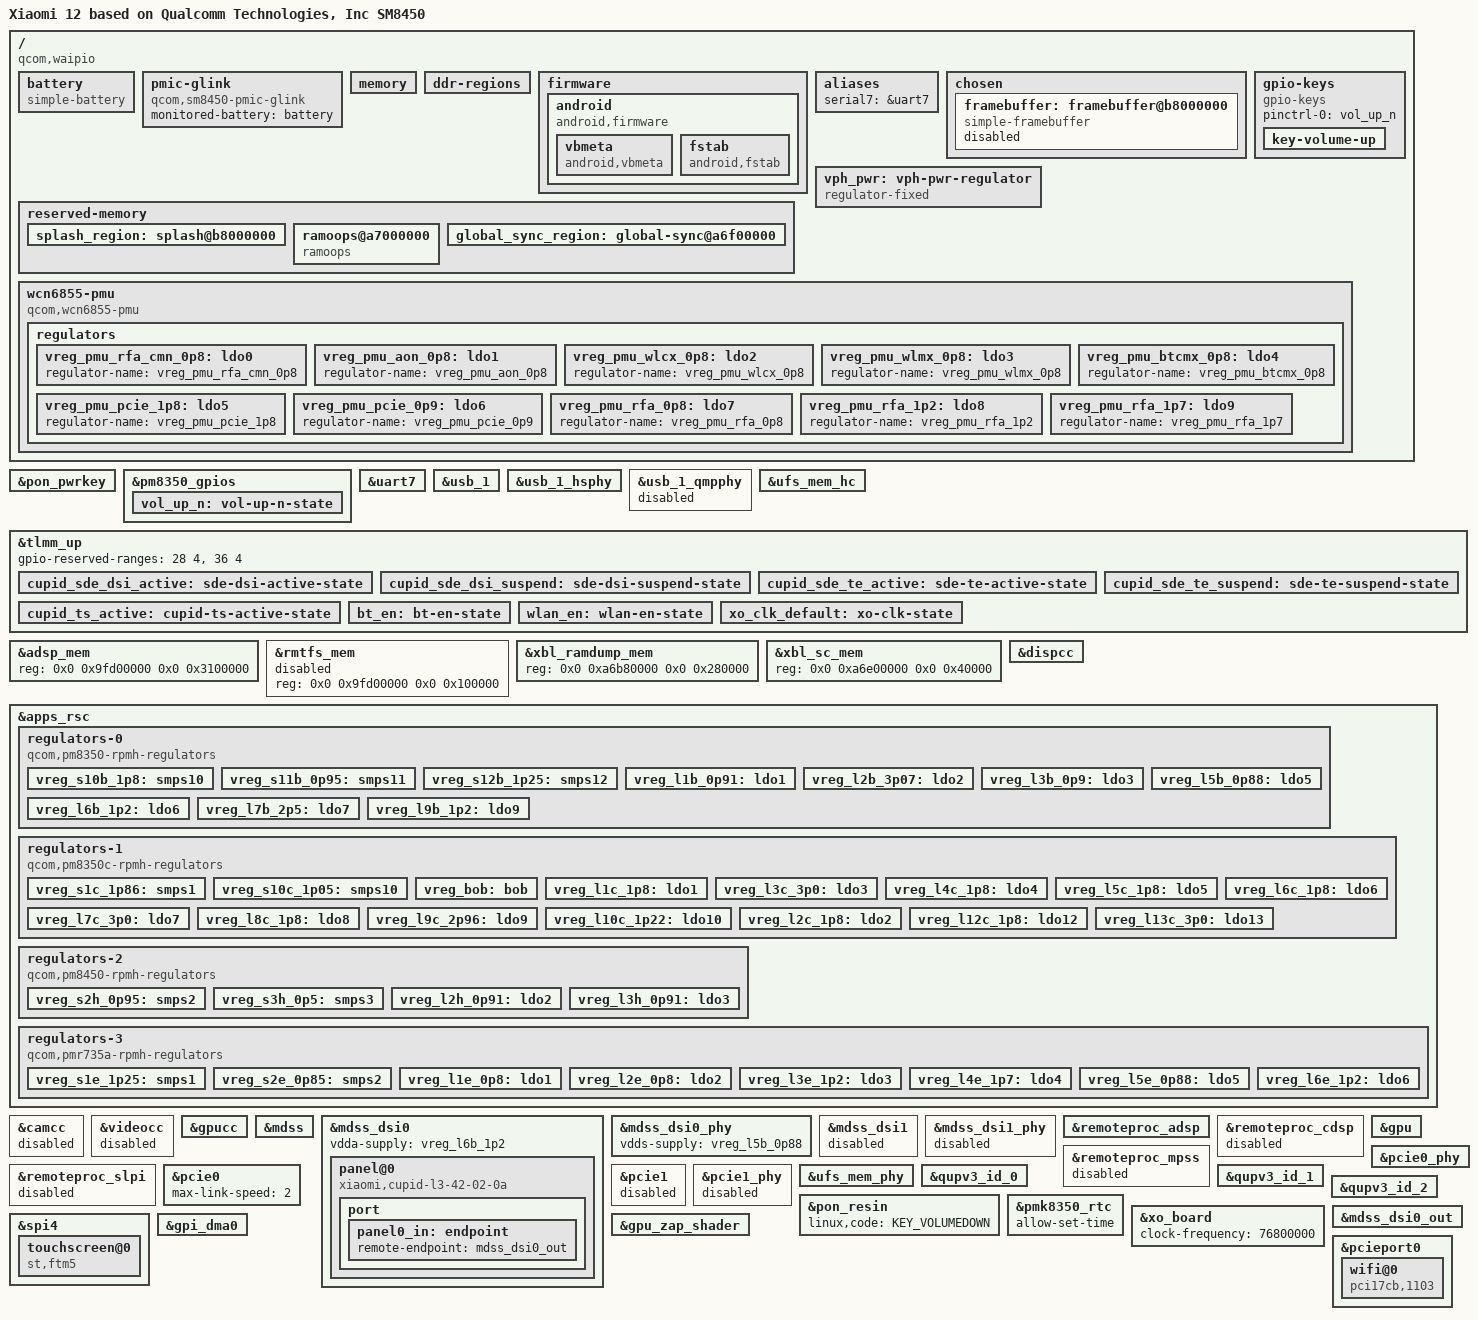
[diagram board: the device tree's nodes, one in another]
// SPDX-License-Identifier: GPL-2.0-only
/*
 * Board device tree for Xiaomi 12 (cupid) ??Qualcomm SM8450 (Snapdragon 8 Gen 1).
 *
 * All values from on-device forensics (2026-10-27):
 *   - runtime device tree (private/device-tree.tar, kernel 5.10.237 vendor build)
 *   - /proc/cmdline, fastboot getvar all, panel modes
 * Reference template: sm8475-xiaomi-marble.dts (same-generation Xiaomi port).
 *
 * Minimal boot set (android-mainline-port step 3): console, USB device mode,
 * UFS, keys, ramoops, borrowed firmware framebuffer. Peripherals (panel
 * native takeover, touch, audio, Wi-Fi) follow in later steps.
 */
/dts-v1/;

#include <dt-bindings/arm/qcom,ids.h>
#include <dt-bindings/gpio/gpio.h>
#include <dt-bindings/input/input.h>
#include <dt-bindings/pinctrl/qcom,pmic-gpio.h>
#include <dt-bindings/regulator/qcom,rpmh-regulator.h>

#include "sm8450.dtsi"
#include "pm8350.dtsi"
#include "pm8350b.dtsi"
#include "pm8350c.dtsi"
#include "pm8450.dtsi"
#include "pmk8350.dtsi"
#include "pmr735a.dtsi"
#include "sm8450-xiaomi-cupid-syms.dtsi"
#include "cupid-cpu-opps.dtsi"

/*
 * XBL allocates firmware carve-outs per device. The SoC dtsi placeholders
 * for adsp/xbl_ramdump/xbl_sc do not match this unit (forensics:
 * adsp@9fd00000, xbl_ramdump@a6b80000, xbl-sc@a6e00000) and are overridden
 * by label at the end of this file. mpss_mem@8bc00000 already matches.
 */

/ {
	model = "Xiaomi 12 based on Qualcomm Technologies, Inc SM8450";
	compatible = "qcom,waipio", "xiaomi,cupid", "qcom,sm8450";
	/*
	 * ABL picks the matching DTB out of the vendor_boot multi-DTB
	 * container by qcom,msm-id + qcom,board-id.
	 *
	 * SM8450 is Waipio: the stock container's waipio entry carries
	 * msm-id <0x1c9 0x10000>, board-id <0 0>. (Entry 0 of the same
	 * container is cape-v2 = SM8475, a different SoC ??do not copy it.)
	 * The values in the runtime /sys/firmware/fdt (<201 0 226 0>) are
	 * what the dtbo overlay wrote over the root afterwards.
	 */
	qcom,msm-id = <0x1c9 0x10000>;
	qcom,board-id = <0x0 0x0>;
	chassis-type = "handset";

	/*
	 * Battery/charger run in ADSP firmware (battmgr) over pmic_glink.
	 * 4500 mAh cell (spec); design voltage assumed ??verify on device.
	 */
	battery: battery {
		compatible = "simple-battery";
		charge-full-design-microamp-hours = <4500000>;
		voltage-min-design-microvolt = <3870000>;
	};

	pmic-glink {
		compatible = "qcom,sm8450-pmic-glink", "qcom,pmic-glink";
		#address-cells = <1>;
		#size-cells = <0>;
		monitored-battery = <&battery>;
	};

	/delete-node/ memory@a0000000;

	/*
	 * 12 GiB LPDDR5, six physical banks from the runtime DT + Android
	 * /proc/iomem System RAM. The stock base DTB leaves /memory empty for
	 * ABL to fill, but ABL does not fill OUR tree (it only patches the
	 * shape it shipped) ??leaving reg empty here means the kernel starts
	 * with zero memory and panics before it can print anything.
	 */
	memory {
		device_type = "memory";
		reg = <0x0 0x80000000 0x0 0x6a000000>,
		      <0x0 0xf4600000 0x0 0x0ba00000>,
		      <0x8 0x00000000 0x0 0x37500000>,
		      <0x8 0x37b00000 0x0 0x01e00000>,
		      <0x8 0x40000000 0x0 0xc0000000>,
		      <0x9 0x00000000 0x1 0x80000000>;
	};

	ddr-regions {
	};

	/* Stock base DTB carries these; keep the same shape for the ABL. */
	firmware {
		android {
			compatible = "android,firmware";

			vbmeta {
				compatible = "android,vbmeta";
				parts = "vbmeta,boot,init_boot,system,vendor,dtbo,recovery";
			};

			fstab {
				compatible = "android,fstab";
			};
		};
	};

	aliases {
		serial7 = &uart7;
	};

	chosen {
		/* reg 解析需要 cells；缺失时 framebuffer 的 reg 无法变成资源，
		 * simpledrm probe 以 -EINVAL 失败（2026-10-31 实测） */
		#address-cells = <2>;
		#size-cells = <2>;
		/*
		 * ABL reads /chosen/bootargs from the device tree (not just the
		 * boot.img header) and appends its own args. Keep it short ??the
		 * bootloader's buffer is ~512 bytes and silently truncates.
		 */
		bootargs = "cupid.fb=0xB8000000,1080,2400,1080,32 clk_ignore_unused pd_ignore_unused regulator_ignore_unused arm-smmu.disable_bypass=0 cpuidle.off=1 console=tty0 console=ttyMSM0,115200n8 quiet loglevel=3 oops=panic softlockup_panic=1 hung_task_panic=1 deferred_probe_timeout=15 panic=30 g_serial.enable=0 g_serial.use_acm=1 rdinit=/init";
		stdout-path = "serial7:115200n8";

		/*
		 * Borrowed firmware display (splash_region, forensics: 0xb8000000
		 * 43 MiB, 1080x2400). First-boot only; native takeover in step 4.
		 * Panel: qcom,mdss_dsi_l3_42_02_0a_dsc_cmd (SeeYA OLED).
		 */
		framebuffer: framebuffer@b8000000 {
			compatible = "simple-framebuffer";
			/* 7.2+ simpledrm 首选 memory-region（aperture 管理），reg 仅回退 */
			memory-region = <&splash_region>;
			reg = <0x0 0xb8000000 0x0 0x2b00000>;
			width = <1080>;
			height = <2400>;
			stride = <(1080 * 4)>;
			format = "a8r8g8b8";
			/* keep the display AXI clock alive ??without it writes to
			 * the borrowed framebuffer do not reach the panel */
			clocks = <&gcc GCC_DISP_HF_AXI_CLK>;
		};
	};

	reserved-memory {
		splash_region: splash@b8000000 {
			reg = <0x0 0xb8000000 0x0 0x2b00000>;
			no-map;
		};

		ramoops@a7000000 {
			compatible = "ramoops";
			reg = <0x0 0xa7000000 0x0 0x400000>;
			record-size = <0x100000>;
			pmsg-size = <0x100000>;
			console-size = <0x200000>;
		};

		global_sync_region: global-sync@a6f00000 {
			reg = <0x0 0xa6f00000 0x0 0x100000>;
			no-map;
		};

		/* TODO(step 6 remotes): slpi@88000000/cdsp@89900000 placeholders
		 * already match this unit; add adsp_heap/audio_cma/spss/spu/va_md/
		 * camera/video/cvp/demura when those subsystems are enabled. */
	};

	gpio-keys {
		compatible = "gpio-keys";
		pinctrl-0 = <&vol_up_n>;
		pinctrl-names = "default";

		key-volume-up {
			label = "Volume Up";
			linux,code = <KEY_VOLUMEUP>;
			/* forensics: pm8350@1 pinctrl key_vol_up; gpio6 per
			 * marble reference ??verify pins in key_vol_up_default */
			gpios = <&pm8350_gpios 6 GPIO_ACTIVE_LOW>;
			debounce-interval = <15>;
			wakeup-source;
		};
	};
};

&pon_pwrkey {
	status = "okay";
};

&pm8350_gpios {
	vol_up_n: vol-up-n-state {
		pins = "gpio6";
		function = PMIC_GPIO_FUNC_NORMAL;
		power-source = <1>;
		bias-pull-up;
		input-enable;
	};
};

&uart7 {
	status = "okay";
};

&usb_1 {
	status = "okay";
	/* netboot phase: device mode for USB NCM debug link.
	 * sm8450.dtsi merges the dwc3 core into usb_1 itself. */
	dr_mode = "peripheral";
};

/* Both PHYs are disabled in sm8450.dtsi ??without them the dwc3
 * controller defers forever and no UDC appears for the gadget. */
&usb_1_hsphy {
	status = "okay";
};

&usb_1_qmpphy {
	status = "okay";
};

&ufs_mem_hc {
	status = "okay";
};

/*
 * GPIO 28-31 / 36-39 belong to TrustZone (stock waipio DTB:
 * qcom,gpios-reserved = <0x1c 0x1d 0x1e 0x1f 0x24 0x25 0x26 0x27>).
 * Without gpio-reserved-ranges the pinctrl driver touches their
 * registers during probe -> XPU violation -> SoC hang + watchdog reset
 * (same failure mode as Xiaomi 13/fuxi, see fuxi-linux notes).
 */
&tlmm_up {
	gpio-reserved-ranges = <28 4>, <36 4>;
};

/* XBL firmware carve-outs, on-device values (forensics) */
&adsp_mem {
	reg = <0x0 0x9fd00000 0x0 0x3100000>;
};

&rmtfs_mem {
	/* No standalone rmtfs on this unit; the dtsi placeholder address
	 * (0x9fd00000) is the ADSP region here. Shrink inside the ADSP
	 * reservation ??harmless overlap, revisited when MSS is enabled. */
	reg = <0x0 0x9fd00000 0x0 0x100000>;
};

&xbl_ramdump_mem {
	reg = <0x0 0xa6b80000 0x0 0x280000>;
};

&xbl_sc_mem {
	reg = <0x0 0xa6e00000 0x0 0x40000>;
};


/*
 * CUPID_MINIMAL_DISABLE (fuxi-style minimal bring-up):
 * sm8450.dtsi leaves every clock controller enabled by default. On this
 * first-batch waipio unit several of them probe hardware regions that
 * hang the SoC (freeze seen at gcc GDSC init and clk driver probes).
 * Keep only gcc + rpmhcc; everything else with a driver in the config
 * gets disabled until its consumer is actually brought up.
 */
&dispcc { status = "disabled"; };

/* apps_rsc 的 power-domains = <&cluster_pd> 依赖 CPU PM domain provider
 * （cpuidle-psci-domain）。本机 PSCI 固件上 SET_SUSPEND_MODE 可能失败导致
 * 整个 provider 注册回滚 -> rpmh-rsc 永久 defer -> 整条 RPMH 链死锁。
 * 先把该属性去掉，让 rpmh-rsc 无 genpd 依赖地 probe（bring-up 期）。 */
&apps_rsc {
	/delete-property/ power-domains;
};
&camcc  { status = "disabled"; };
&videocc { status = "disabled"; };
&gpucc  { status = "disabled"; };

/* display pipe stays dark until the panel driver lands (step 4) */
&mdss { status = "disabled"; };
&mdss_dsi0 { status = "disabled"; };
&mdss_dsi0_phy { status = "disabled"; };
&mdss_dsi1 { status = "disabled"; };
&mdss_dsi1_phy { status = "disabled"; };

/* remotes need firmware we do not ship yet */
&remoteproc_adsp { status = "disabled"; };
&remoteproc_cdsp { status = "disabled"; };
&remoteproc_mpss { status = "disabled"; };
&remoteproc_slpi { status = "disabled"; };

/* GPU not in minimal config */
&gpu { status = "disabled"; };

/* PCIe/WiFi for a later step */
&pcie0 { status = "disabled"; };
&pcie0_phy { status = "disabled"; };
&pcie1 { status = "disabled"; };
&pcie1_phy { status = "disabled"; };

/* ===== FUXI_ALIGNMENT_BLOCK =====
 * Regulators + UFS/USB wiring copied from the E-011 graft (originally from
 * sm8450-qrd.dts). It made ABL reject the image when the DTB was shipped in
 * the boot image, but with CUPID_FORCE_BUILTIN_DTB ABL never sees our tree,
 * so the graft is safe now. fuxi proves the same structure boots on Xiaomi
 * hardware of the adjacent generation.
 */
/* ===== regulators: copied from sm8450-qrd.dts (same SoC + same PMIC set) ===== */
/ {
	vph_pwr: vph-pwr-regulator {
		compatible = "regulator-fixed";
		regulator-name = "vph_pwr";
		regulator-min-microvolt = <3700000>;
		regulator-max-microvolt = <3700000>;

		regulator-always-on;
		regulator-boot-on;
	};

};

&apps_rsc {
	regulators-0 {
		compatible = "qcom,pm8350-rpmh-regulators";
		qcom,pmic-id = "b";

		vdd-s1-supply = <&vph_pwr>;
		vdd-s2-supply = <&vph_pwr>;
		vdd-s3-supply = <&vph_pwr>;
		vdd-s4-supply = <&vph_pwr>;
		vdd-s5-supply = <&vph_pwr>;
		vdd-s6-supply = <&vph_pwr>;
		vdd-s7-supply = <&vph_pwr>;
		vdd-s8-supply = <&vph_pwr>;
		vdd-s9-supply = <&vph_pwr>;
		vdd-s10-supply = <&vph_pwr>;
		vdd-s11-supply = <&vph_pwr>;
		vdd-s12-supply = <&vph_pwr>;

		vdd-l1-l4-supply = <&vreg_s11b_0p95>;
		vdd-l2-l7-supply = <&vreg_bob>;
		vdd-l3-l5-supply = <&vreg_bob>;
		vdd-l6-l9-l10-supply = <&vreg_s12b_1p25>;
		vdd-l8-supply = <&vreg_s2h_0p95>;

		vreg_s10b_1p8: smps10 {
			regulator-name = "vreg_s10b_1p8";
			regulator-min-microvolt = <1800000>;
			regulator-max-microvolt = <1800000>;
		};

		vreg_s11b_0p95: smps11 {
			regulator-name = "vreg_s11b_0p95";
			regulator-min-microvolt = <848000>;
			regulator-max-microvolt = <1104000>;
		};

		vreg_s12b_1p25: smps12 {
			regulator-name = "vreg_s12b_1p25";
			regulator-min-microvolt = <1224000>;
			regulator-max-microvolt = <1400000>;
		};

		vreg_l1b_0p91: ldo1 {
			regulator-name = "vreg_l1b_0p91";
			regulator-min-microvolt = <912000>;
			regulator-max-microvolt = <920000>;
			regulator-initial-mode = <RPMH_REGULATOR_MODE_HPM>;
		};

		vreg_l2b_3p07: ldo2 {
			regulator-name = "vreg_l2b_3p07";
			regulator-min-microvolt = <3072000>;
			regulator-max-microvolt = <3072000>;
			regulator-initial-mode = <RPMH_REGULATOR_MODE_HPM>;
		};

		vreg_l3b_0p9: ldo3 {
			regulator-name = "vreg_l3b_0p9";
			regulator-min-microvolt = <904000>;
			regulator-max-microvolt = <904000>;
			regulator-initial-mode = <RPMH_REGULATOR_MODE_HPM>;
		};

		vreg_l5b_0p88: ldo5 {
			regulator-name = "vreg_l5b_0p88";
			regulator-min-microvolt = <880000>;
			regulator-max-microvolt = <888000>;
			regulator-initial-mode = <RPMH_REGULATOR_MODE_HPM>;
		};

		vreg_l6b_1p2: ldo6 {
			regulator-name = "vreg_l6b_1p2";
			regulator-min-microvolt = <1200000>;
			regulator-max-microvolt = <1200000>;
			regulator-initial-mode = <RPMH_REGULATOR_MODE_HPM>;
		};

		vreg_l7b_2p5: ldo7 {
			regulator-name = "vreg_l7b_2p5";
			regulator-min-microvolt = <2504000>;
			regulator-max-microvolt = <2504000>;
			regulator-initial-mode = <RPMH_REGULATOR_MODE_HPM>;
		};

		vreg_l9b_1p2: ldo9 {
			regulator-name = "vreg_l9b_1p2";
			regulator-min-microvolt = <1200000>;
			regulator-max-microvolt = <1200000>;
			regulator-initial-mode = <RPMH_REGULATOR_MODE_HPM>;
		};
	};

	regulators-1 {
		compatible = "qcom,pm8350c-rpmh-regulators";
		qcom,pmic-id = "c";

		vdd-s1-supply = <&vph_pwr>;
		vdd-s2-supply = <&vph_pwr>;
		vdd-s3-supply = <&vph_pwr>;
		vdd-s4-supply = <&vph_pwr>;
		vdd-s5-supply = <&vph_pwr>;
		vdd-s6-supply = <&vph_pwr>;
		vdd-s7-supply = <&vph_pwr>;
		vdd-s8-supply = <&vph_pwr>;
		vdd-s9-supply = <&vph_pwr>;
		vdd-s10-supply = <&vph_pwr>;

		vdd-l1-l12-supply = <&vreg_bob>;
		vdd-l2-l8-supply = <&vreg_bob>;
		vdd-l3-l4-l5-l7-l13-supply = <&vreg_bob>;
		vdd-l6-l9-l11-supply = <&vreg_bob>;

		vdd-bob-supply = <&vph_pwr>;

		vreg_s1c_1p86: smps1 {
			regulator-name = "vreg_s1c_1p86";
			regulator-min-microvolt = <1800000>;
			regulator-max-microvolt = <2024000>;
		};

		vreg_s10c_1p05: smps10 {
			regulator-name = "vreg_s10c_1p05";
			regulator-min-microvolt = <1000000>;
			regulator-max-microvolt = <1100000>;
		};

		vreg_bob: bob {
			regulator-name = "vreg_bob";
			regulator-min-microvolt = <3008000>;
			regulator-max-microvolt = <3960000>;
			regulator-initial-mode = <RPMH_REGULATOR_MODE_AUTO>;
		};

		vreg_l1c_1p8: ldo1 {
			regulator-name = "vreg_l1c_1p8";
			regulator-min-microvolt = <1800000>;
			regulator-max-microvolt = <1800000>;
			regulator-initial-mode = <RPMH_REGULATOR_MODE_HPM>;
		};

		vreg_l3c_3p0: ldo3 {
			regulator-name = "vreg_l3c_3p0";
			regulator-min-microvolt = <3296000>;
			regulator-max-microvolt = <3304000>;
			regulator-initial-mode = <RPMH_REGULATOR_MODE_HPM>;
		};

		vreg_l4c_1p8: ldo4 {
			regulator-name = "vreg_l4c_1p8";
			regulator-min-microvolt = <1704000>;
			regulator-max-microvolt = <3000000>;
			regulator-initial-mode = <RPMH_REGULATOR_MODE_HPM>;
		};

		vreg_l5c_1p8: ldo5 {
			regulator-name = "vreg_l5c_1p8";
			regulator-min-microvolt = <1704000>;
			regulator-max-microvolt = <3000000>;
			regulator-initial-mode = <RPMH_REGULATOR_MODE_HPM>;
		};

		vreg_l6c_1p8: ldo6 {
			regulator-name = "vreg_l6c_1p8";
			regulator-min-microvolt = <1800000>;
			regulator-max-microvolt = <3008000>;
			regulator-initial-mode = <RPMH_REGULATOR_MODE_HPM>;
		};

		vreg_l7c_3p0: ldo7 {
			regulator-name = "vreg_l7c_3p0";
			regulator-min-microvolt = <3008000>;
			regulator-max-microvolt = <3008000>;
			regulator-initial-mode = <RPMH_REGULATOR_MODE_HPM>;
		};

		vreg_l8c_1p8: ldo8 {
			regulator-name = "vreg_l8c_1p8";
			regulator-min-microvolt = <1800000>;
			regulator-max-microvolt = <1800000>;
			regulator-initial-mode = <RPMH_REGULATOR_MODE_HPM>;
		};

		vreg_l9c_2p96: ldo9 {
			regulator-name = "vreg_l9c_2p96";
			regulator-min-microvolt = <2960000>;
			regulator-max-microvolt = <3008000>;
			regulator-initial-mode = <RPMH_REGULATOR_MODE_HPM>;
		};

		vreg_l10c_1p22: ldo10 {
			regulator-name = "vreg_l10c_1p22";
			regulator-min-microvolt = <1200000>;
			regulator-max-microvolt = <1220000>;
			regulator-initial-mode = <RPMH_REGULATOR_MODE_HPM>;
		};

		vreg_l2c_1p8: ldo2 {
			regulator-name = "vreg_l2c_1p8";
			regulator-min-microvolt = <1800000>;
			regulator-max-microvolt = <1800000>;
			regulator-initial-mode = <RPMH_REGULATOR_MODE_HPM>;
		};

		vreg_l12c_1p8: ldo12 {
			regulator-name = "vreg_l12c_1p8";
			regulator-min-microvolt = <1800000>;
			regulator-max-microvolt = <1968000>;
			regulator-initial-mode = <RPMH_REGULATOR_MODE_HPM>;
		};

		vreg_l13c_3p0: ldo13 {
			regulator-name = "vreg_l13c_3p0";
			regulator-min-microvolt = <3000000>;
			regulator-max-microvolt = <3000000>;
			regulator-initial-mode = <RPMH_REGULATOR_MODE_HPM>;
		};
	};

	regulators-2 {
		compatible = "qcom,pm8450-rpmh-regulators";
		qcom,pmic-id = "h";

		vdd-s1-supply = <&vph_pwr>;
		vdd-s2-supply = <&vph_pwr>;
		vdd-s3-supply = <&vph_pwr>;
		vdd-s4-supply = <&vph_pwr>;
		vdd-s5-supply = <&vph_pwr>;
		vdd-s6-supply = <&vph_pwr>;

		vdd-l2-supply = <&vreg_bob>;
		vdd-l3-supply = <&vreg_bob>;
		vdd-l4-supply = <&vreg_bob>;

		vreg_s2h_0p95: smps2 {
			regulator-name = "vreg_s2h_0p95";
			regulator-min-microvolt = <848000>;
			regulator-max-microvolt = <1104000>;
		};

		vreg_s3h_0p5: smps3 {
			regulator-name = "vreg_s3h_0p5";
			regulator-min-microvolt = <500000>;
			regulator-max-microvolt = <500000>;
		};

		vreg_l2h_0p91: ldo2 {
			regulator-name = "vreg_l2h_0p91";
			regulator-min-microvolt = <880000>;
			regulator-max-microvolt = <912000>;
			regulator-initial-mode = <RPMH_REGULATOR_MODE_HPM>;
		};

		vreg_l3h_0p91: ldo3 {
			regulator-name = "vreg_l3h_0p91";
			regulator-min-microvolt = <912000>;
			regulator-max-microvolt = <912000>;
			regulator-initial-mode = <RPMH_REGULATOR_MODE_HPM>;
		};
	};

	regulators-3 {
		compatible = "qcom,pmr735a-rpmh-regulators";
		qcom,pmic-id = "e";

		vdd-s1-supply = <&vph_pwr>;
		vdd-s2-supply = <&vph_pwr>;
		vdd-s3-supply = <&vph_pwr>;

		vdd-l1-l2-supply = <&vreg_s2e_0p85>;
		vdd-l3-supply = <&vreg_s1e_1p25>;
		vdd-l4-supply = <&vreg_s1c_1p86>;
		vdd-l5-l6-supply = <&vreg_s1c_1p86>;
		vdd-l7-bob-supply = <&vreg_bob>;

		vreg_s1e_1p25: smps1 {
			regulator-name = "vreg_s1e_1p25";
			regulator-min-microvolt = <1200000>;
			regulator-max-microvolt = <1296000>;
		};

		vreg_s2e_0p85: smps2 {
			regulator-name = "vreg_s2e_0p85";
			regulator-min-microvolt = <500000>;
			regulator-max-microvolt = <1040000>;
		};

		vreg_l1e_0p8: ldo1 {
			regulator-name = "vreg_l1e_0p8";
			regulator-min-microvolt = <800000>;
			regulator-max-microvolt = <800000>;
		};

		vreg_l2e_0p8: ldo2 {
			regulator-name = "vreg_l2e_0p8";
			regulator-min-microvolt = <800000>;
			regulator-max-microvolt = <800000>;
		};

		vreg_l3e_1p2: ldo3 {
			regulator-name = "vreg_l3e_1p2";
			regulator-min-microvolt = <1200000>;
			regulator-max-microvolt = <1200000>;
		};

		vreg_l4e_1p7: ldo4 {
			regulator-name = "vreg_l4e_1p7";
			regulator-min-microvolt = <1776000>;
			regulator-max-microvolt = <1776000>;
		};

		vreg_l5e_0p88: ldo5 {
			regulator-name = "vreg_l5e_0p88";
			regulator-min-microvolt = <880000>;
			regulator-max-microvolt = <880000>;
		};

		vreg_l6e_1p2: ldo6 {
			regulator-name = "vreg_l6e_1p2";
			regulator-min-microvolt = <1200000>;
			regulator-max-microvolt = <1200000>;
		};
	};
};

/* ===== UFS / USB wiring (from sm8450-qrd.dts, verified against live DT) ===== */
&ufs_mem_hc {
	status = "okay";
	reset-gpios = <&tlmm_up 210 GPIO_ACTIVE_LOW>;
	vcc-supply = <&vreg_l7b_2p5>;
	vcc-max-microamp = <1100000>;
	vccq-supply = <&vreg_l9b_1p2>;
	vccq-max-microamp = <1200000>;
	vdd-hba-supply = <&vreg_l9b_1p2>;
};

&ufs_mem_phy {
	status = "okay";
	vdda-phy-supply = <&vreg_l5b_0p88>;
	vdda-pll-supply = <&vreg_l6b_1p2>;
};

&usb_1_hsphy {
	status = "okay";
	vdda-pll-supply = <&vreg_l5b_0p88>;
	vdda18-supply = <&vreg_l1c_1p8>;
	vdda33-supply = <&vreg_l2b_3p07>;
};

/* fuxi alignment: QUP wrappers + GPI DMA (skill pitfall L78-83: without
 * these, serial engines never register), xo_board freq, pon_resin key,
 * eUSB2 repeater supplies */
&qupv3_id_0 { status = "okay"; };
&qupv3_id_1 { status = "okay"; };
&qupv3_id_2 { status = "okay"; };

&pon_resin {
	linux,code = <KEY_VOLUMEDOWN>;
	status = "okay";
};

/* PMK8350 RTC: the only time source that survives a power cycle. */
&pmk8350_rtc {
	allow-set-time;
	status = "okay";
};

&xo_board {
	clock-frequency = <76800000>;
};

/* FUXI_USB_ALIGN: skill usb-and-storage.md L123 ? QMP USB3/DP PHY ??????
 * ???????????fuxi ?????? HS PHY?USB2 ????QMP ???
 * ? UTMI ? pipe ?????"??????"??? USB ??? */
&usb_1 {
	/delete-property/ usb-role-switch;
	phys = <&usb_1_hsphy>;
	phy-names = "usb2-phy";
	maximum-speed = "high-speed";
	qcom,select-utmi-as-pipe-clk;
	dr_mode = "peripheral";
	status = "okay";
};

&usb_1_qmpphy {
	status = "disabled";
};


/* ===== DISPLAY (v-disp variant): MSM/DPU + DSI0 + 5nm PHY + panel ===== */
&framebuffer {
	status = "disabled";
};

&dispcc {
	status = "okay";
};

&mdss {
	status = "okay";
};

&mdss_dsi0 {
	vdda-supply = <&vreg_l6b_1p2>;
	status = "okay";

	panel@0 {
		compatible = "xiaomi,cupid-l3-42-02-0a";
		reg = <0>;

		pinctrl-0 = <&cupid_sde_dsi_active>, <&cupid_sde_te_active>;
		pinctrl-1 = <&cupid_sde_dsi_suspend>, <&cupid_sde_te_suspend>;
		pinctrl-names = "default", "sleep";

		reset-gpios = <&tlmm_up 0 GPIO_ACTIVE_HIGH>;

		vddio-supply = <&vreg_l12c_1p8>;
		vddd-supply = <&vreg_l10c_1p22>;
		vci-supply = <&vreg_l13c_3p0>;

		port {
			panel0_in: endpoint {
				remote-endpoint = <&mdss_dsi0_out>;
			};
		};
	};
};

&mdss_dsi0_out {
	remote-endpoint = <&panel0_in>;
	data-lanes = <0 1 2 3>;
};

&mdss_dsi0_phy {
	vdds-supply = <&vreg_l5b_0p88>;
	status = "okay";
};

&tlmm_up {
	cupid_sde_dsi_active: sde-dsi-active-state {
		pins = "gpio0";
		function = "gpio";
		drive-strength = <8>;
		bias-disable;
	};

	cupid_sde_dsi_suspend: sde-dsi-suspend-state {
		pins = "gpio0";
		function = "gpio";
		drive-strength = <2>;
		bias-pull-down;
	};

	cupid_sde_te_active: sde-te-active-state {
		pins = "gpio86";
		function = "mdp_vsync";
		drive-strength = <2>;
		bias-pull-down;
	};

	cupid_sde_te_suspend: sde-te-suspend-state {
		pins = "gpio86";
		function = "mdp_vsync";
		drive-strength = <2>;
		bias-pull-down;
	};
};


/* ===== TOUCH (v-touch variant): ST FTS on QUP2 SE4 (spi@990000) ===== */
&qupv3_id_2 {
	status = "okay";
};

&spi4 {
	status = "okay";

	touchscreen@0 {
		compatible = "st,ftm5";
		reg = <0>;
		spi-max-frequency = <12000000>;

		interrupt-parent = <&tlmm_up>;
		interrupts = <21 IRQ_TYPE_LEVEL_LOW>;

		reset-gpios = <&tlmm_up 20 GPIO_ACTIVE_LOW>;

		vdd-supply = <&vreg_l2c_1p8>;
		avdd-supply = <&vreg_l7c_3p0>;

		pinctrl-0 = <&cupid_ts_active>;
		pinctrl-names = "default";

		touchscreen-size-x = <10800>;
		touchscreen-size-y = <24000>;
	};
};

&tlmm_up {
	cupid_ts_active: cupid-ts-active-state {
		pins = "gpio20", "gpio21";
		function = "gpio";
		drive-strength = <8>;
		bias-pull-up;
	};
};

&gpi_dma0 {
	status = "okay";
};

/* ===== CUPID_GPU_ENABLE (v55): Adreno 730 bring-up ===== */
&gpucc { status = "okay"; };
&gpu { status = "okay"; };
&gpu_zap_shader {
	firmware-name = "qcom/sm8450/xiaomi/cupid/a730_zap.mdt";
};

/* ===== CUPID_ADSP_ENABLE (v56): ADSP + PMIC GLINK battery monitor ===== */
&rmtfs_mem {
	status = "disabled";
};

&remoteproc_adsp {
	firmware-name = "qcom/sm8450/xiaomi/cupid/adsp.mdt";
	status = "okay";
};
/* ===== CUPID_WIFI_ENABLE (v61): QCA6490 on pcie0 + WCN6855 PMU ===== */
/ {
	wcn6855-pmu {
		compatible = "qcom,wcn6855-pmu";

		pinctrl-0 = <&bt_en>, <&wlan_en>, <&xo_clk_default>;
		pinctrl-names = "default";

		wlan-enable-gpios = <&tlmm_up 80 GPIO_ACTIVE_HIGH>;
		bt-enable-gpios = <&tlmm_up 81 GPIO_ACTIVE_HIGH>;
		swctrl-gpios = <&tlmm_up 82 GPIO_ACTIVE_HIGH>;
		xo-clk-gpios = <&tlmm_up 204 GPIO_ACTIVE_HIGH>;

		vddio-supply = <&vreg_s10b_1p8>;
		vddaon-supply = <&vreg_s11b_0p95>;
		vddpmu-supply = <&vreg_s12b_1p25>;
		vddpmumx-supply = <&vreg_s2e_0p85>;
		vddpmucx-supply = <&vreg_s11b_0p95>;
		vddrfa0p95-supply = <&vreg_s11b_0p95>;
		vddrfa1p3-supply = <&vreg_s12b_1p25>;
		vddrfa1p9-supply = <&vreg_s1c_1p86>;
		vddpcie1p3-supply = <&vreg_s12b_1p25>;
		vddpcie1p9-supply = <&vreg_s1c_1p86>;

		regulators {
			vreg_pmu_rfa_cmn_0p8: ldo0 {
				regulator-name = "vreg_pmu_rfa_cmn_0p8";
			};

			vreg_pmu_aon_0p8: ldo1 {
				regulator-name = "vreg_pmu_aon_0p8";
			};

			vreg_pmu_wlcx_0p8: ldo2 {
				regulator-name = "vreg_pmu_wlcx_0p8";
			};

			vreg_pmu_wlmx_0p8: ldo3 {
				regulator-name = "vreg_pmu_wlmx_0p8";
			};

			vreg_pmu_btcmx_0p8: ldo4 {
				regulator-name = "vreg_pmu_btcmx_0p8";
			};

			vreg_pmu_pcie_1p8: ldo5 {
				regulator-name = "vreg_pmu_pcie_1p8";
			};

			vreg_pmu_pcie_0p9: ldo6 {
				regulator-name = "vreg_pmu_pcie_0p9";
			};

			vreg_pmu_rfa_0p8: ldo7 {
				regulator-name = "vreg_pmu_rfa_0p8";
			};

			vreg_pmu_rfa_1p2: ldo8 {
				regulator-name = "vreg_pmu_rfa_1p2";
			};

			vreg_pmu_rfa_1p7: ldo9 {
				regulator-name = "vreg_pmu_rfa_1p7";
			};
		};
	};
};

&pcie0 {
	status = "okay";
	max-link-speed = <2>;
};

&pcie0_phy {
	status = "okay";
	vdda-phy-supply = <&vreg_l5b_0p88>;
	vdda-pll-supply = <&vreg_l6b_1p2>;
};

&pcieport0 {
	wifi@0 {
		compatible = "pci17cb,1103";
		reg = <0x10000 0x0 0x0 0x0 0x0>;

		vddrfacmn-supply = <&vreg_pmu_rfa_cmn_0p8>;
		vddaon-supply = <&vreg_pmu_aon_0p8>;
		vddwlcx-supply = <&vreg_pmu_wlcx_0p8>;
		vddwlmx-supply = <&vreg_pmu_wlmx_0p8>;
		vddpcie1p8-supply = <&vreg_pmu_pcie_1p8>;
		vddpcie0p9-supply = <&vreg_pmu_pcie_0p9>;
		vddrfa0p8-supply = <&vreg_pmu_rfa_0p8>;
		vddrfa1p2-supply = <&vreg_pmu_rfa_1p2>;
		vddrfa1p8-supply = <&vreg_pmu_rfa_1p7>;
	};
};

&tlmm_up {
	bt_en: bt-en-state {
		pins = "gpio81";
		function = "gpio";
		drive-strength = <16>;
		output-low;
		bias-pull-down;
	};

	wlan_en: wlan-en-state {
		pins = "gpio80";
		function = "gpio";
		drive-strength = <16>;
		output-low;
		bias-pull-down;
	};

	xo_clk_default: xo-clk-state {
		pins = "gpio204";
		function = "gpio";
		drive-strength = <16>;
		output-low;
		bias-pull-down;
	};
};
